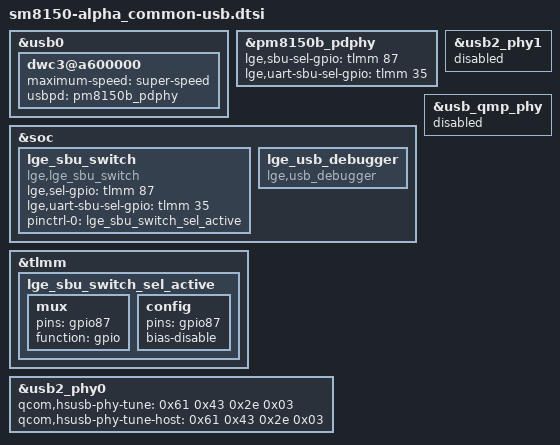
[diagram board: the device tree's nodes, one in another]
/*
 * Copyright (c) 2018, The Linux Foundation. All rights reserved.
 *
 * This program is free software; you can redistribute it and/or modify
 * it under the terms of the GNU General Public License version 2 and
 * only version 2 as published by the Free Software Foundation.
 *
 * This program is distributed in the hope that it will be useful,
 * but WITHOUT ANY WARRANTY; without even the implied warranty of
 * MERCHANTABILITY or FITNESS FOR A PARTICULAR PURPOSE.  See the
 * GNU General Public License for more details.
 */

&usb0 {
	dwc3@a600000 {
		maximum-speed = "super-speed";
		usbpd = <&pm8150b_pdphy>;
	};
};

&pm8150b_pdphy {
	lge,sbu-sel-gpio = <&tlmm 87 0>;
	lge,uart-sbu-sel-gpio = <&tlmm 35 0>;
};

/*
 * LGE USB Type-C CC/SBU Protection Switch driver
 */
&soc {
	lge_sbu_switch: lge_sbu_switch {
		compatible = "lge,lge_sbu_switch";

		lge,sel-gpio = <&tlmm 87 0>;
		lge,uart-sbu-sel-gpio = <&tlmm 35 0>;
		/* lge,ovp-gpio */

		pinctrl-names = "default";
		pinctrl-0 = <&lge_sbu_switch_sel_active /* &lge_sbu_switch_ovp_active */>;
	};
};

&tlmm {
	lge_sbu_switch_sel_active: lge_sbu_switch_sel_active {
		mux {
			pins = "gpio87";
			function = "gpio";
		};

		config {
			pins = "gpio87";
			bias-disable;
		};
	};

	/*
	lge_sbu_switch_ovp_active: lge_sbu_switch_ovp_active {
		mux {
			pins = "gpio79";
			function = "gpio";
		};

		config {
			pins = "gpio79";
			bias-pull-up;
		};
	};
	*/
};

/*
 * LGE USB UART debugger driver
 */
&soc {
	lge_usb_debugger: lge_usb_debugger {
		compatible = "lge,usb_debugger";
	};
};

&usb2_phy0 {
	qcom,hsusb-phy-tune = <0x61 0x43 0x2e 0x03>;
	qcom,hsusb-phy-tune-host = <0x61 0x43 0x2e 0x03>;
};

&usb2_phy1 {
	status = "disabled";
};

&usb_qmp_phy {
	status = "disabled";
};
